# D1H.pdf register map
Vendor: Allwinner; Series: D1H.pdf; File version: 0.1
CPU: XuanTie C906 RISC-V CPU 0, little endian, MPU, FPU, double-precision FPU, 0 interrupt priority bits
Registers are 32-bit, read-write, reset 0x0 unless marked. A register's access mark holds for its fields unless they carry their own. Offsets are from the block's base; [hi:lo] are bit positions; 'fields as' and 'values as' point back to an identical list.

## TVE
Base 0x05604000
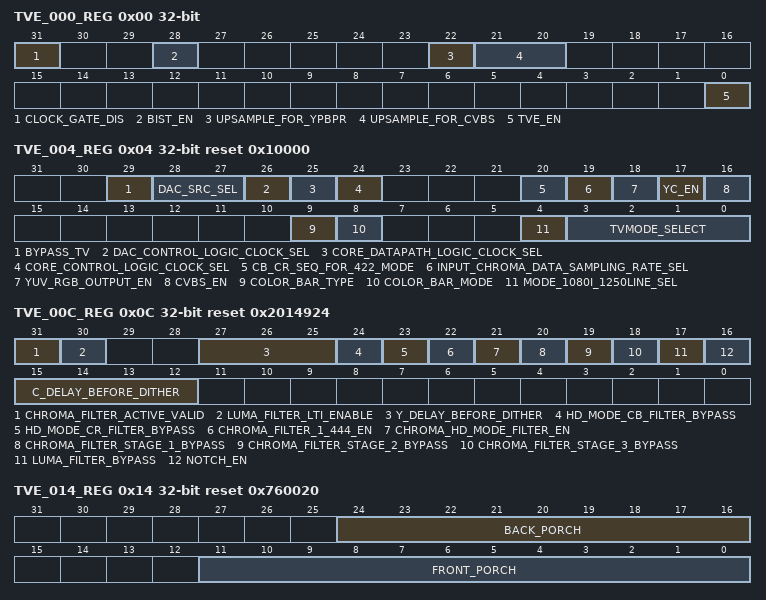
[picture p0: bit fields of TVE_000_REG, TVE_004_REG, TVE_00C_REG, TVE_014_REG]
0x00 TVE_000_REG — TV Encoder Clock Gating Register
  [31] CLOCK_GATE_DIS — 0: Enable 1: Disable
    0=Enable; 1=Disable
  [28] BIST_EN — 0: Normal mode 1: Bist mode
    0=Normal_mode; 1=Bist_mode
  [22] UPSAMPLE_FOR_YPBPR — 0: 1x 1: 2x
    0=_1x; 1=_2x
  [21:20] UPSAMPLE_FOR_CVBS — Out up sample 00: 27 MHz 01: 54 MHz 10: 108 MHz 11: 216 MHz
    0=27 MHz; 1=54 MHz; 2=108 MHz; 3=216 MHz
  [0] TVE_EN — 0: Disable 1: Enable Video Encoder enable, default disable, write 1 to take it out of the reset state
    0=Disable; 1=Enable Video Encoder enable, default disable, write 1 to take it out of the reset state
0x04 TVE_004_REG reset 0x10000 — TV Encoder Configuration Register
  [29] BYPASS_TV — 0: Disable 1: Enable
    0=Disable; 1=Enable
  [28:27] DAC_SRC_SEL — 00: TV Encoder 01: LCD controller, override all other TV encoder setting, the DAC clock can from LCD controller. 10: DAC test mode, DAC using DAC clock 11: DAC test mode, DAC using AHB clock
  [26] DAC_CONTROL_LOGIC_CLOCK_SEL — 0: Using 27 MHz clock or 74.25 MHz clock depend on CCU setting 1: Using 54 MHz clock or 148.5 MHz clock depend on CCU setting
    0=Using 27 MHz clock or 74.25 MHz clock depend on CCU setting; 1=Using 54 MHz clock or 148.5 MHz clock depend on CCU setting
  [25] CORE_DATAPATH_LOGIC_CLOCK_SEL — 0: Using 27 MHz clock or 74.25 MHz clock depend on CCU setting 1: Using 54 MHz clock or 148.5 MHz clock depend on CCU setting
    values as DAC_CONTROL_LOGIC_CLOCK_SEL
  [24] CORE_CONTROL_LOGIC_CLOCK_SEL — 0: Using 27 MHz clock or 74.25 MHz clock depend on CCU setting 1: Using 54 MHz clock or 148.5 MHz clock depend on CCU setting
    values as DAC_CONTROL_LOGIC_CLOCK_SEL
  [20] CB_CR_SEQ_FOR_422_MODE — Cb_Cr_Seq_For_422_Mode 0: Cb first 1: Cr first
    0=Cb (Cb first); 1=Cr (Cr first)
  [19] INPUT_CHROMA_DATA_SAMPLING_RATE_SEL — 0: 4:4:4 1: 4:2:2
    0=_4_colon_4_colon_4 (4:4:4); 1=_4_colon_2_colon_2 (4:2:2)
  [18] YUV_RGB_OUTPUT_EN — 0: CVBS 1: Reserved
    0=CVBS
  [17] YC_EN — S-port Video enable Selection. 0: Y/C is disable 1: Reserved This bit selects whether the S-port(Y/C) video output is enabled or disabled.
    0=Y_slash_C (Y/C is disable)
  [16] CVBS_EN — Composite video enables selection 0: Composite video is disabled, Only Y/C is enabled 1: Composite video is enabled., CVBS and Y/C are enabled This bit selects whether the composite video output (CVBS) is enabled or disabled.
    0=disabled (Composite video is disabled, Only Y/C is enabled); 1=enabled (Composite video is enabled., CVBS and Y/C are enabled This bit selects whether the composite video output (CVBS) is enabled or disabled.)
  [9] COLOR_BAR_TYPE — 0: 75/7.5/75/7.5 (NTSC), 100/0/75/0(PAL) 1: 100/7.5/100/7.5(NTSC), 100/0/100/0(PAL)
    0=_75_slash_7_point_5_slash_75_slash_7_point_5 (75/7.5/75/7.5 (NTSC), 100/0/75/0(PAL)); 1=_100_slash_7_point_5_slash_100_slash_7_point_5_openingparen_NTSC_closingparen_ (100/7.5/100/7.5(NTSC), 100/0/100/0(PAL))
  [8] COLOR_BAR_MODE — Standard Color bar input selection 0: The Video Encoder input is coming from the Display Engineer 1: The Video Encoder input is coming from an internal standard color bar generator. This bit selects whether the Video Encoder video data input is replaced by an internal standard color bar generator or not.
    0=coming_from_the_Display (The Video Encoder input is coming from the Display Engineer); 1=coming_from_an (The Video Encoder input is coming from an internal standard color bar generator. This bit selects whether the Video Encoder video data input is replaced by an internal standard color bar generator or not.)
  [4] MODE_1080I_1250LINE_SEL — Mode_1080i_1250Line_Sel 0: 1125 Line mode 1: 1250 Line mode
    0=1125 Line mode; 1=1250 Line mode
  [3:0] TVMODE_SELECT — TVMode_Select 0000: NTSC 0001: PAL 0010: Reserved 0011: Reserved 01xx: Reserved 100x: Reserved 101x: Reserved 110x: Reserved 111x: Reserved Note: Changing this register value will cause some relative register setting to relative value.
    0=NTSC; 1=PAL
0x08 TVE_008_REG — TV Encoder DAC Register1
  [6:4] DAC0_SRC_SEL — 000: Composite Others: Reserved
    0=Composite
0x0C TVE_00C_REG reset 0x2014924 — TV Encoder Notch and DAC Delay Register
  [31] CHROMA_FILTER_ACTIVE_VALID — 0: Disable 1: Enable
    0=Disable; 1=Enable
  [30] LUMA_FILTER_LTI_ENABLE — Luma_filter_lti_enable 0: Disable Luma filter lti 1: Enable Luma filter lti
    0=Disable Luma filter lti; 1=Enable Luma filter lti
  [27:25] Y_DELAY_BEFORE_DITHER
  [24] HD_MODE_CB_FILTER_BYPASS — 0: Bypass Enable 1: Bypass Disable
    0=Bypass_Enable; 1=Bypass_Disable
  [23] HD_MODE_CR_FILTER_BYPASS — 0: Bypass Enable 1: Bypass Disable
    0=Bypass_Enable; 1=Bypass_Disable
  [22] CHROMA_FILTER_1_444_EN — Chroma_Filter_1_444_En 0: Chroma Filter 1 444 Disable 1: Chroma Filter 1 444 Enable
    0=Chroma_Filter_1_444_Disable; 1=Chroma_Filter_1_444_Enable
  [21] CHROMA_HD_MODE_FILTER_EN — 0: Chroma HD Filter Disable 1: Chroma HD Filter Enable
    0=Chroma_HD_Filter_Disable; 1=Chroma_HD_Filter_Enable
  [20] CHROMA_FILTER_STAGE_1_BYPASS — Chroma_Filter_Stage_1_Bypass 0: Chroma Filter Stage 1 Enable 1: Chroma Filter Stage 1 bypass
    0=Chroma_Filter_Stage_1_Enable; 1=Chroma_Filter_Stage_1_bypass
  [19] CHROMA_FILTER_STAGE_2_BYPASS — Chroma_Filter_Stage_2_Bypass 0: Chroma Filter Stage 2 Enable 1: Chroma Filter Stage 2 bypass
    0=Chroma_Filter_Stage_2_Enable; 1=Chroma_Filter_Stage_2_bypass
  [18] CHROMA_FILTER_STAGE_3_BYPASS — Chroma_Filter_Stage_3_Bypass 0: Chroma Filter Stage 3 Enable 1: Chroma Filter Stage 3 bypass
    0=Chroma_Filter_Stage_3_Enable; 1=Chroma_Filter_Stage_3_bypass
  [17] LUMA_FILTER_BYPASS — 0: Luma Filter Enable 1: Luma Filter bypass
    0=Luma_Filter_Enable; 1=Luma_Filter_bypass
  [16] NOTCH_EN — 0: The luma notch filter is bypassed 1: The luma notch filter is operating Luma notch filter on/off selection Note: This bit selects if the luma notch filter is operating or bypassed.
    0=bypassed (The luma notch filter is bypassed); 1=operating (The luma notch filter is operating Luma notch filter on/off selection Note: This bit selects if the luma notch filter is operating or bypassed.)
  [15:12] C_DELAY_BEFORE_DITHER
0x10 TVE_010_REG reset 0x21F07C1F — TV Encoder Chroma Frequency Register
  [31:0] CHROMA_FREQ — Specify the ratio between the color burst frequency. 32 bits unsigned fraction. The default value is h21f07c1f, which is compatible with NTSC spec. 3.5795455 MHz (X‘21F07C1F’): NTSC-M, NTSC-J 4.43361875 MHz(X‘2A098ACB’): PAL-B, D, G, H,I, N 3.582056 MHz (X‘21F69446’): PAL-N(Argentina) 3.579611 MHz (X‘21E6EFE3’): PAL-M
0x14 TVE_014_REG reset 0x760020 — TV Encoder Front/Back Porch Register
  [24:16] BACK_PORCH — Specify the width of the back porch in encoder clock cycles. Min value is (burst_width+breeze_way+17). 8 bits unsigned integer. The default value is 118. For 720p mode, the value is 260. For 1080i/p mode, the value is 192.
  [11:0] FRONT_PORCH — Must be even Specify the width of the front porch in encoder clock cycles. 6 bits unsigned even integer. Allowed range is form 10 to 62. The default value is 32. For 1080i mode, the value is 44.
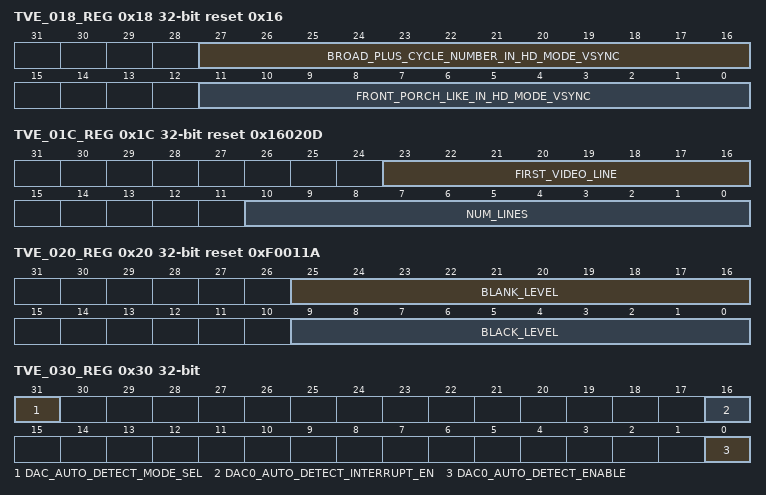
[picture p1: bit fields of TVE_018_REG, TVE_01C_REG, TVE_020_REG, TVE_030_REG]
0x18 TVE_018_REG reset 0x16 — TV Encoder HD Mode VSYNC Register
  [27:16] BROAD_PLUS_CYCLE_NUMBER_IN_HD_MODE_VSYNC, [11:0] FRONT_PORCH_LIKE_IN_HD_MODE_VSYNC
0x1C TVE_01C_REG reset 0x16020D — TV Encoder Line Number Register
  [23:16] FIRST_VIDEO_LINE — Specify the index of the first line in a field/frame to have active video. 8 bits unsigned integer. For interlaced video: When VSync5=B‘0’, FirstVideoLine is restricted to be greater than 7. When VSync5=B‘1’, FirstVideoLine is restricted to be greater than 9.
  [10:0] NUM_LINES — Specify the total number of lines in a video frame. 11 bits unsigned integer. Allowed range is 0 to 2048. For interlaced video: When NTSC, and FirstVideoLine is greater than 20, then NumLines is restricted to be greater than 2*(FirstVideoLine+18). When NTSC, and FirstVideoLine is not greater than 20, then NumLines is restricted to be greater than 77. When PAL, and FirstVideoLine is greater than 22, then NumLines is restricted to be greater than 2*(FirstVideoLine+18). When PAL, and FirstVideoLine is not greater than 22, then NumLines is restricted to be greater than 81. If NumLines is even, then it is restricted to be divisible by 4. If NumLines is odd, then it is restricted to be divisible by 4 with a remainder of 1.
0x20 TVE_020_REG reset 0xF0011A — TV Encoder Level Register
  [25:16] BLANK_LEVEL — Specify the blank level setting for active lines. This is 10 bits unsigned integer. Allowed range is from 0 to 1023.
  [9:0] BLACK_LEVEL — Specify the black level setting. This is 10 bits unsigned integer. Allowed range is from 240 to 1023.
0x30 TVE_030_REG — TV Encoder Auto Detection Enable Register
  [31] DAC_AUTO_DETECT_MODE_SEL — 0: Old Mode 1: New Mode
    0=Old (Old Mode); 1=New (New Mode)
  [16] DAC0_AUTO_DETECT_INTERRUPT_EN
  [0] DAC0_AUTO_DETECT_ENABLE
0x34 TVE_034_REG — TV Encoder Auto Detection Interrupt Status Register
  [0] DAC0_AUTO_DETECT_INTERRUPT_ACTIVE_FLAG write-1-clears — Write 1 to inactive DAC0 auto detection interrupt
0x38 TVE_038_REG — TV Encoder Auto Detection Status Register
  [1:0] DAC0_STATUS ro — 00: Unconnected 01: Connected 11: Short to ground 10: Reserved
    0=Unconnected; 1=Connected; 3=Short to ground
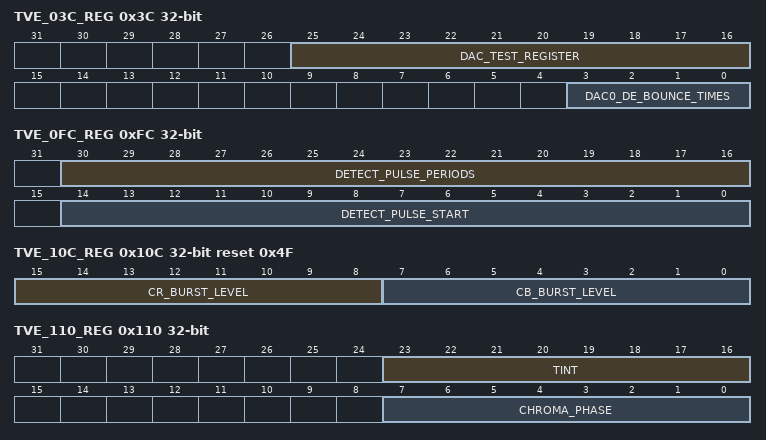
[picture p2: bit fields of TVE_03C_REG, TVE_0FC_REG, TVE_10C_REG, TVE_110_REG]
0x3C TVE_03C_REG — TV Encoder Auto Detection De-bounce Setting Register
  [25:16] DAC_TEST_REGISTER
  [3:0] DAC0_DE_BOUNCE_TIMES — The de_bounce time for hot plug detect function.
0xF8 TVE_0F8_REG — TV Encoder Auto Detect Configuration Register0
  [9:0] DETECT_PULSE_VALUE — Use for DAC data input at auto detect pluse. Set the pulse amplitude.
0xFC TVE_0FC_REG — TV Encoder Auto Detect Configuration Register1
  [30:16] DETECT_PULSE_PERIODS — Use 32K clock
  [14:0] DETECT_PULSE_START — Detect signal start time
0x100 TVE_100_REG reset 0x1 — TV Encoder Color Burst Phase Reset Configuration Register
  [1:0] COLOR_PHASE_RESET — Color burst phase period selection These bits select the number of fields or lines after which the color burst phase is reset to its initial value as specified by the ChromaPhase parameter, This parameter is application only for interlaced video. 00: 8 field 01: 4 field 10: 2 lines 11: only once
    0=_8; 1=_4; 2=2 lines; 3=only_once
0x104 TVE_104_REG — TV Encoder VSYNC Number Register
  [0] VSYNC5 — VSync5 Number of equalization pulse selection This bit selects whether the number of equalization pulses is 5 or 6. This parameter is applicable only for interlaced video. 0: 5 equalization pulse(default) 1: 6 equalization pulses
    0=5 equalization pulse(default); 1=6 equalization pulses
0x108 TVE_108_REG reset 0x2 — TV Encoder Notch Filter Frequency Register
  [2:0] NOTCH_FREQ — Luma notch filter center frequency selection These bits select the luma notch filter (which is a band-reject filter) center frequency. In two of the selections, the filter width affects also the selection of the center frequency. 000: 1.1875 001: 1.1406 010: 1.0938. When notch_wide value is B‘1’ (this selection is proper for CCIR-NTSC), or 1.0000 when notch_wide value is B‘0’. 011: 0.9922. This selection is proper for NTSC with square pixels. 100: 0.9531. This selection is proper for PAL with square pixel. 101: 0.8359 when notch_wide value is B‘1’ (this selection is proper for CCIR-PAL), or 0.7734 when notch_wide value is B‘0’. 110: 0.7813 111: 0.7188
    0=_1_point_1875 (1.1875); 1=_1_point_1406 (1.1406); 2=_1_point_0938 (1.0938. When notch_wide value is B‘1’ (this selection is proper for CCIR-NTSC), or 1.0000 when notch_wide value is B‘0’.); 3=_0_point_9922 (0.9922. This selection is proper for NTSC with square pixels.); 4=_0_point_9531 (0.9531. This selection is proper for PAL with square pixel.); 5=_0_point_8359 (0.8359 when notch_wide value is B‘1’ (this selection is proper for CCIR-PAL), or 0.7734 when notch_wide value is B‘0’.); 6=_0_point_7813 (0.7813); 7=_0_point_7188 (0.7188)
0x10C TVE_10C_REG reset 0x4F — TV Encoder Cb/Cr Level/Gain Register
  [15:8] CR_BURST_LEVEL — Specify the amplitude of the Cr burst. 8 bit 2’s complement integer. Allowed range is from (-127) to 127.
  [7:0] CB_BURST_LEVEL — Specify the amplitude of the Cb burst. 8 bit 2’s complement integer. Allowed range is from (-127) to 127.
0x110 TVE_110_REG — TV Encoder Tint and Color Burst Phase Register
  [23:16] TINT — Tint Specify the tint adjustment of the chroma signal for CVBS and Y/C outputs. The adjustment is effected by setting the sub- carrier phase to the value of this parameter. 8.8 bit unsigned fraction. Units are cycles of the color burst frequency.
  [7:0] CHROMA_PHASE — Specify the color burst initial phase (ChromaPhase). 8.8 bit unsigned fraction. Units are cycles of the color burst frequency. The color burst is set to this phase at the first HSYNC and then reset to the same value at further HSYNCs as specified by the CPhaseRset bits of the EncConfig5 parameter (see above)
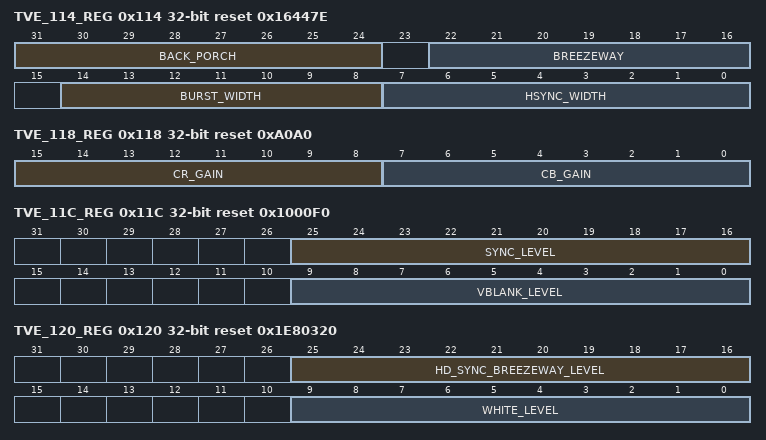
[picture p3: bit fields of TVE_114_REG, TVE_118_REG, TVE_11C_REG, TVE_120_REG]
0x114 TVE_114_REG reset 0x16447E — TV Encoder Burst Width Register
  [31:24] BACK_PORCH — Breezeway like in HD mode VSync For 720p mode, the value is 220 For 2080i/p mode, the value is 88 (default)
  [22:16] BREEZEWAY — Breezeway Must be even Specify the width of the breezeway in encoder clock cycles. 5 bit unsigned integer. Allowed range is 0 to 31. For 1080i mode, the value is 44. For 1080p mode, the value is 44. For 720p mode, the value is 40.
  [14:8] BURST_WIDTH — Specify the width of the color frequency burst in encoder clock cycles. 7 bit unsigned integer. Allowed range is 0 to 127. In hd mode, it is ignored.
  [7:0] HSYNC_WIDTH — HSync_Width Specify the width of the horizontal sync pulse in encoder clock cycles. Min value is 16. Max value is (FrontPorch + ActiveLine - BackPorch). Default value is 126. The sum of HSyncSize and BackPorch is restricted to be divisible by 4. For 720p mode, the value is 40. For 1080i/p mode, the value is 44.
0x118 TVE_118_REG reset 0xA0A0 — TV Encoder Cb/Cr Gain Register
  [15:8] CR_GAIN — Specify the Cr color gain. 8-bit unsigned fraction.
  [7:0] CB_GAIN — Specify the Cb color gain. 8-bit unsigned fraction.
0x11C TVE_11C_REG reset 0x1000F0 — TV Encoder Sync and VBI Level Register
  [25:16] SYNC_LEVEL — Specify the sync pulse level setting. 8-bit unsigned integer. Allowed range is from 0 to ABlankLevel-1 or VBlankLevel-1 (whichever is smaller).
  [9:0] VBLANK_LEVEL — VBlank_Level Specify the blank level setting for non active lines. 10-bit unsigned integer. Allow range is from 0 to 1023.
0x120 TVE_120_REG reset 0x1E80320 — TV Encoder White Level Register
  [25:16] HD_SYNC_BREEZEWAY_LEVEL — Specify the breezeway level setting. 10-bit unsigned integer. Allowed range is from 0 to 1023.
  [9:0] WHITE_LEVEL — Specify the white level setting. 10-bit unsigned integer. Allowed range is from black_level+1 or vbi_blank_level +1 (whichever is greater) to 1023.
0x124 TVE_124_REG reset 0x5A0 — TV Encoder Video Active Line Register
  [11:0] ACTIVE_LINE — Specify the width of the video line in encoder clock cycles. 12- bit unsigned multiple of 4 integer. Allowed range is from 0 to 4092.
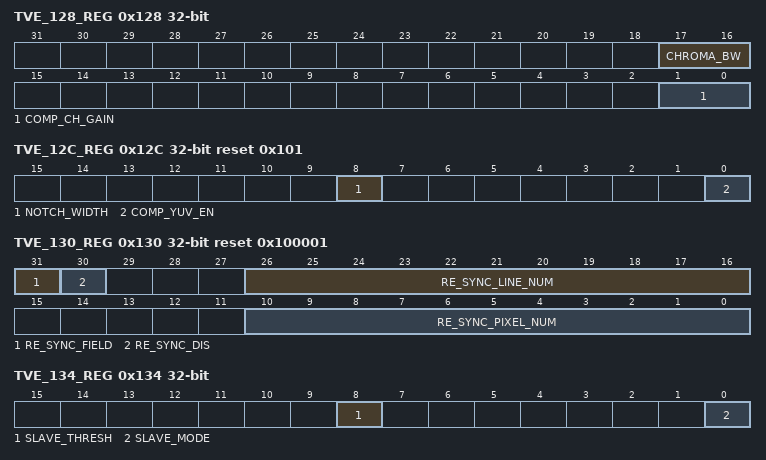
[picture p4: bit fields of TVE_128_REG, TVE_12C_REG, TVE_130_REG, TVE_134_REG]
0x128 TVE_128_REG — TV Encoder Video Chroma BW and CompGain Register
  [17:16] CHROMA_BW — Chroma filter bandwidth selection This bit specifies whether the bandwidth of the chroma filter is: 00: Narrow width 0.6 MHz 01: Wide width 1.2 MHz 10: Extra width 1.8 MHz 11: Ultra width 2.5 MHz
    0=Narrow width 0.6 MHz; 1=Wide width 1.2 MHz; 2=Extra width 1.8 MHz; 3=Ultra width 2.5 MHz
  [1:0] COMP_CH_GAIN — Chroma gain selection for the composite video signal. These bits specify the gain of the chroma signal for composing with the luma signal to generate the composite video signal: 00: 100% 01: 25% 10: 50% 11: 75%
    0=_100_percent_; 1=_25_percent_; 2=_50_percent_; 3=_75_percent_
0x12C TVE_12C_REG reset 0x101 — TV Encoder Register
  [8] NOTCH_WIDTH — Luma notch filter width selection This bit selects the luma notch filter (which is a band-reject filter) width. 0: Narrow 1: Wide
    0=Narrow; 1=Wide
  [0] COMP_YUV_EN — This bit selects if the components video output are the RGB components or the YUV components. 0: The three component outputs are the RGB components. 1: The three component outputs are the YUV components, (i.e. the color conversion unit is bypassed)
    0=three_component_outputs_are_the_RGB (The three component outputs are the RGB components.); 1=three_component_outputs_are_the_YUV (The three component outputs are the YUV components, (i.e. the color conversion unit is bypassed))
0x130 TVE_130_REG reset 0x100001 — TV Encoder Re-sync Parameters Register
  [31] RE_SYNC_FIELD
  [30] RE_SYNC_DIS — 0: Re-Sync Enable 1: Re-Sync Disable
    0=re_Sync_Enable; 1=re_Sync_Disable
  [26:16] RE_SYNC_LINE_NUM — Re-sync line number from TCON
  [10:0] RE_SYNC_PIXEL_NUM — Re-sync line pixel from TCON
0x134 TVE_134_REG — TV Encoder Slave Parameter Register
  [8] SLAVE_THRESH — Horizontal line adjustment threshold selection This bit selects whether the number of lines after which the Video Encoder starts the horizontal line length adjustment is slave mode is 0 or 30. 0: Number of lines is 0 1: Number of lines is 30
    0=Number of lines is 0; 1=Number of lines is 30
  [0] SLAVE_MODE — Slave mode selection This bit selects whether the Video Encoder is sync slave, partial slave or sync master. It should be set to B‘0’. 0: The Video Encoder is not a full sync slave (i.e. it is a partial sync slave or a sync master) 1: Reserved
    0=Video (The Video Encoder is not a full sync slave (i.e. it is a partial sync slave or a sync master))
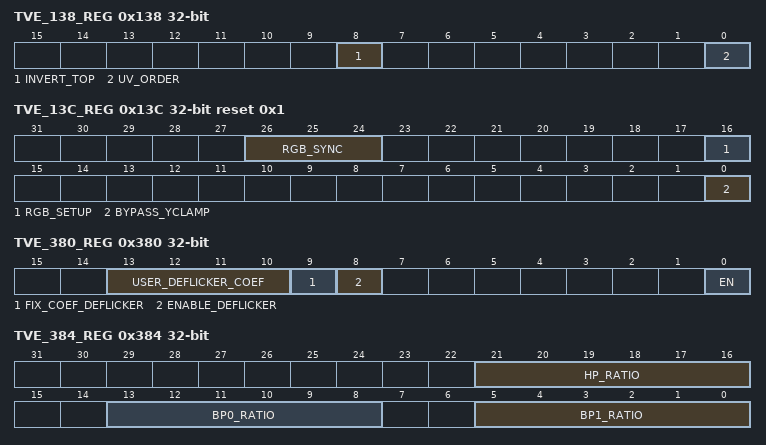
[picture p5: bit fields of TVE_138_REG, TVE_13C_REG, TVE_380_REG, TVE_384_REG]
0x138 TVE_138_REG — TV Encoder Configuration Register0
  [8] INVERT_TOP — Field parity input signal (top_field) polarity selection. This bit selects whether the top field is indicated by a high level of the field parity signal or by the low level. The bit is applicable both when the Video Encoder is the sync master and when the Video Encoder is the sync slave. 0: Top field is indicated by low level 1: Top field is indicated by high level
    0=indicated_by_low_level (Top field is indicated by low level); 1=indicated_by_high_level (Top field is indicated by high level)
  [0] UV_ORDER — This bit selects if the sample order at the chroma input to the Video Encoder is Cb first (i.e. Cb 0 Cr 0 Cb 1 Cr 1) or Cr first (i.e. Cr 0 Cb 0 Cr 1 Cb 1). 0: The chroma sample input order is Cb first 1: The chroma sample input order is Cr first
    0=Cb (The chroma sample input order is Cb first); 1=Cr (The chroma sample input order is Cr first)
0x13C TVE_13C_REG reset 0x1 — TV Encoder Configuration Register1
  [26:24] RGB_SYNC — R, G and B signals sync embedding selection. These bits specify whether the sync signal is added to each of the R, G and B components (b‘1’) or not (b‘0’). The bit[26] specify if the R signal has embedded syncs, the bit[25] specify if the G signal has embedded syncs and the bit[24] specify if the B signal has embedded syncs. When comp_yuv is equal to b‘1’, these bits are N.A. and should be set to b‘000’. When the value is different from b‘000’, RGB_Setup should be set to b‘1’.
  [16] RGB_SETUP — “Set-up” enable for RGB outputs. This bit specifies if the “set-up” implied value (black_level – blank_level) specified for the CVBS signal is used also for the RGB signals. 0: The “set-up” is not used, or i.e. comp_yuv is equal to b‘1’. 1: The implied “set-up” is used for the RGB signals
    0=set_up (The “set-up” is not used, or i.e. comp_yuv is equal to b‘1’.); 1=implied (The implied “set-up” is used for the RGB signals)
  [0] BYPASS_YCLAMP — Y input clamping selection This bit selects whether the Video Encoder Y input is clamped to 64 to 940 or not. When not clamped the expected range is 0 to 1023. The U and V inputs are always clamped to the range 64 to 960. 0: The Video Encoder Y input is clamped 1: The Video Encoder Y input is not clamped
    0=clamped (The Video Encoder Y input is clamped); 1=not_clamped (The Video Encoder Y input is not clamped)
0x380 TVE_380_REG — TV Encoder Low Pass Control Register
  [13:10] USER_DEFLICKER_COEF — User_deflicker_coef up: coef/32 Center: 1-coef/16 Down: coef/32
  [9] FIX_COEF_DEFLICKER — Fix_coef_deflicker 0: Auto deflicker 1: User deflicker
    0=Auto deflicker; 1=User deflicker
  [8] ENABLE_DEFLICKER — Enable_deflicker 0: Disable deflicker 1: Enable deflicker
    0=Disable deflicker; 1=Enable deflicker
  [0] EN — LP function enable 0: Disable 1: Enable
    0=Disable; 1=Enable
0x384 TVE_384_REG — TV Encoder Low Pass Filter Control Register
  [21:16] HP_RATIO — Default high-pass filter ratio In two complement, the range is from -31 to 31.
  [13:8] BP0_RATIO — Default band-pass filter0 ratio In two complement, the range is from -31 to 31.
  [5:0] BP1_RATIO — Default band-pass filter1 ratio In two complement, the range is from -31 to 31.
0x388 TVE_388_REG — TV Encoder Low Pass Gain Register
  [7:0] GAIN — Peaking gain setting.
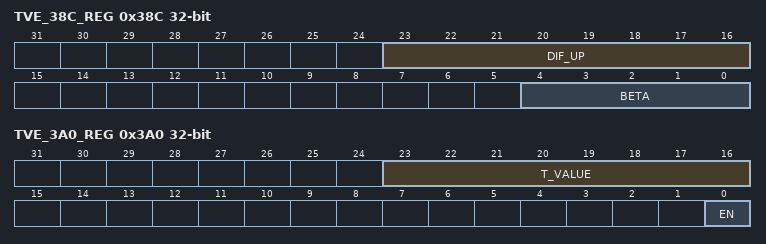
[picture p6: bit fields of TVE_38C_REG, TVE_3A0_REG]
0x38C TVE_38C_REG — TV Encoder Low Pass Gain Control Register
  [23:16] DIF_UP — Gain control: limitation threshold.
  [4:0] BETA — Gain control: large gain limitation.
0x390 TVE_390_REG — TV Encoder Low Pass Shoot Control Register
  [5:0] NEG_GAIN — Undershoot gain control.
0x394 TVE_394_REG — TV Encoder Low Pass Coring Register
  [7:0] CORTHR — Coring threshold.
0x3A0 TVE_3A0_REG — TV Encoder Noise Reduction Register
  [23:16] T_VALUE, [0] EN
